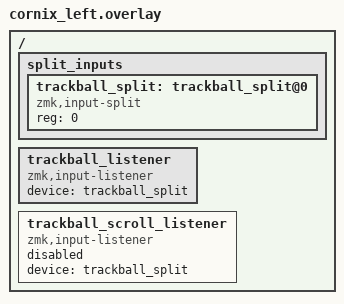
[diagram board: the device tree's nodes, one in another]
// Split input configuration (central side - receives trackball data from peripheral)
/{
    split_inputs {
        #address-cells = <1>;
        #size-cells = <0>;

        trackball_split: trackball_split@0 {
            compatible = "zmk,input-split";
            reg = <0>;
        };
    };

    trackball_listener: trackball_listener {
        compatible = "zmk,input-listener";
        device = <&trackball_split>;
        status = "okay";

        // Input processors will be configured in keymap file
    };

    trackball_scroll_listener: trackball_scroll_listener {
        compatible = "zmk,input-listener";
        device = <&trackball_split>;
        status = "disabled";

        // Scroll mode: converts XY movement to scroll wheel events
    };
};
